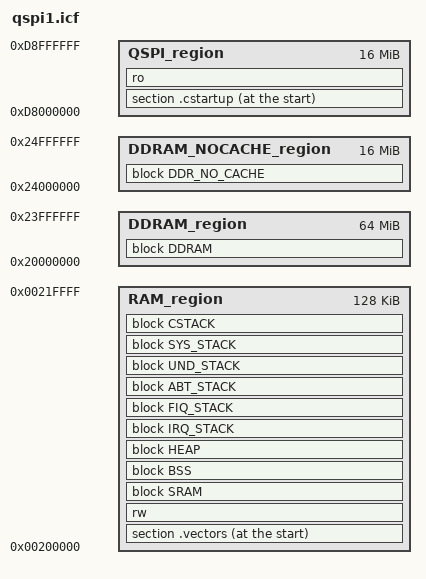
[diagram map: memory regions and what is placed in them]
define memory mem with size = 4G;
define region RAM_region           = mem:[from 0x00200000 to 0x0021FFFF];
define region DDRAM_region         = mem:[from 0x20000000 to 0x23FFFFFF];
define region DDRAM_NOCACHE_region = mem:[from 0x24000000 to 0x24FFFFFF];
define region QSPI_region          = mem:[from 0xD8000000 to 0xD8FFFFFF];

define block CSTACK    with alignment = 8, size = 0x3000 { };
define block IRQ_STACK with alignment = 8, size = 0x60   { };
define block FIQ_STACK with alignment = 8, size = 0x60   { };
define block ABT_STACK with alignment = 8, size = 0x40   { };
define block UND_STACK with alignment = 8, size = 0x40   { };
define block SYS_STACK with alignment = 8, size = 0x40   { };
define block HEAP      with alignment = 4, size = 0x200 { };

define block BSS with alignment = 32 { zi };

define block SRAM  with alignment = 32 { section .region_sram  };
define block DDRAM with alignment = 32 { section .region_ddr };

define block DDR_NO_CACHE { section .region_ddr_nocache };

initialize by copy with packing=none { rw };
initialize by copy with packing=none { section .vectors };
do not initialize { section .region_sram };
do not initialize { section .region_ddr };
do not initialize { section .region_ddr_nocache };

place at start of RAM_region { section .vectors };
place in RAM_region { rw };
place in RAM_region { block SRAM };
place in RAM_region { block BSS };
place in RAM_region { block HEAP };
place in RAM_region { block IRQ_STACK };
place in RAM_region { block FIQ_STACK };
place in RAM_region { block ABT_STACK };
place in RAM_region { block UND_STACK };
place in RAM_region { block SYS_STACK };
place in RAM_region { block CSTACK };

place at start of QSPI_region { section .cstartup };
place in QSPI_region { ro };

place in DDRAM_region { block DDRAM };

place in DDRAM_NOCACHE_region { block DDR_NO_CACHE };
